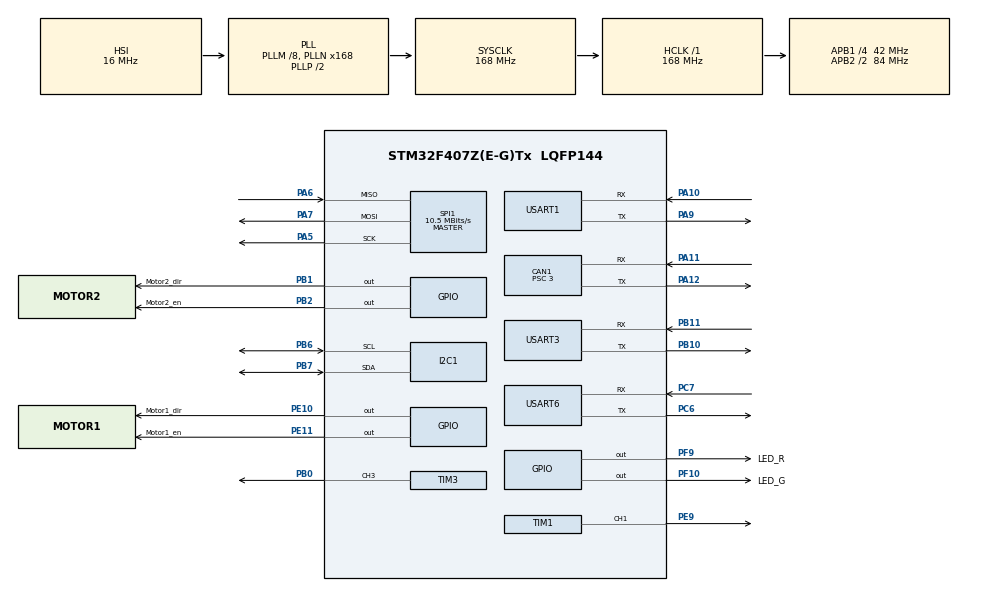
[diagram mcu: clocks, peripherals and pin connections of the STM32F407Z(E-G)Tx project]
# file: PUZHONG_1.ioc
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CAN1.ABOM=ENABLE
CAN1.BS1=CAN_BS1_10TQ
CAN1.BS2=CAN_BS2_3TQ
CAN1.CalculateBaudRate=1000000
CAN1.CalculateTimeBit=1000
CAN1.CalculateTimeQuantum=71.42857142857143
CAN1.Prescaler=3
Dma.Request0=USART3_RX
Dma.Request1=USART1_RX
Dma.Request2=USART1_TX
Dma.Request3=USART6_RX
Dma.Request4=USART3_TX
Dma.Request5=TIM1_CH1
Dma.TIM1_CH1.5.Direction=DMA_MEMORY_TO_PERIPH
Dma.TIM1_CH1.5.FIFOMode=DMA_FIFOMODE_DISABLE
Dma.TIM1_CH1.5.Instance=DMA2_Stream1
Dma.TIM1_CH1.5.MemDataAlignment=DMA_MDATAALIGN_HALFWORD
Dma.TIM1_CH1.5.MemInc=DMA_MINC_ENABLE
Dma.TIM1_CH1.5.Mode=DMA_NORMAL
Dma.TIM1_CH1.5.PeriphDataAlignment=DMA_PDATAALIGN_HALFWORD
Dma.TIM1_CH1.5.PeriphInc=DMA_PINC_DISABLE
Dma.TIM1_CH1.5.Priority=DMA_PRIORITY_MEDIUM
Dma.USART1_RX.1.Direction=DMA_PERIPH_TO_MEMORY
Dma.USART1_RX.1.FIFOMode=DMA_FIFOMODE_DISABLE
Dma.USART1_RX.1.Instance=DMA2_Stream5
Dma.USART1_RX.1.MemDataAlignment=DMA_MDATAALIGN_BYTE
Dma.USART1_RX.1.MemInc=DMA_MINC_ENABLE
Dma.USART1_RX.1.Mode=DMA_NORMAL
Dma.USART1_RX.1.PeriphDataAlignment=DMA_PDATAALIGN_BYTE
Dma.USART1_RX.1.PeriphInc=DMA_PINC_DISABLE
Dma.USART1_RX.1.Priority=DMA_PRIORITY_LOW
Dma.USART1_TX.2.Direction=DMA_MEMORY_TO_PERIPH
Dma.USART1_TX.2.FIFOMode=DMA_FIFOMODE_DISABLE
Dma.USART1_TX.2.Instance=DMA2_Stream7
Dma.USART1_TX.2.MemDataAlignment=DMA_MDATAALIGN_BYTE
Dma.USART1_TX.2.MemInc=DMA_MINC_ENABLE
Dma.USART1_TX.2.Mode=DMA_NORMAL
Dma.USART1_TX.2.PeriphDataAlignment=DMA_PDATAALIGN_BYTE
Dma.USART1_TX.2.PeriphInc=DMA_PINC_DISABLE
Dma.USART1_TX.2.Priority=DMA_PRIORITY_LOW
Dma.USART3_RX.0.Direction=DMA_PERIPH_TO_MEMORY
Dma.USART3_RX.0.FIFOMode=DMA_FIFOMODE_DISABLE
Dma.USART3_RX.0.Instance=DMA1_Stream1
Dma.USART3_RX.0.MemDataAlignment=DMA_MDATAALIGN_BYTE
Dma.USART3_RX.0.MemInc=DMA_MINC_ENABLE
Dma.USART3_RX.0.Mode=DMA_CIRCULAR
Dma.USART3_RX.0.PeriphDataAlignment=DMA_PDATAALIGN_BYTE
Dma.USART3_RX.0.PeriphInc=DMA_PINC_DISABLE
Dma.USART3_RX.0.Priority=DMA_PRIORITY_LOW
Dma.USART3_TX.4.Direction=DMA_MEMORY_TO_PERIPH
Dma.USART3_TX.4.FIFOMode=DMA_FIFOMODE_DISABLE
Dma.USART3_TX.4.Instance=DMA1_Stream3
Dma.USART3_TX.4.MemDataAlignment=DMA_MDATAALIGN_BYTE
Dma.USART3_TX.4.MemInc=DMA_MINC_ENABLE
Dma.USART3_TX.4.Mode=DMA_CIRCULAR
Dma.USART3_TX.4.PeriphDataAlignment=DMA_PDATAALIGN_BYTE
Dma.USART3_TX.4.PeriphInc=DMA_PINC_DISABLE
Dma.USART3_TX.4.Priority=DMA_PRIORITY_LOW
Dma.USART6_RX.3.Direction=DMA_PERIPH_TO_MEMORY
Dma.USART6_RX.3.FIFOMode=DMA_FIFOMODE_DISABLE
Dma.USART6_RX.3.Instance=DMA2_Stream2
Dma.USART6_RX.3.MemDataAlignment=DMA_MDATAALIGN_BYTE
Dma.USART6_RX.3.MemInc=DMA_MINC_ENABLE
Dma.USART6_RX.3.Mode=DMA_NORMAL
Dma.USART6_RX.3.PeriphDataAlignment=DMA_PDATAALIGN_BYTE
Dma.USART6_RX.3.PeriphInc=DMA_PINC_DISABLE
Dma.USART6_RX.3.Priority=DMA_PRIORITY_LOW
FREERTOS.BinarySemaphores01=can_cmd_sem,Dynamic,NULL,Available
FREERTOS.INCLUDE_eTaskGetState=1
FREERTOS.INCLUDE_pcTaskGetTaskName=1
FREERTOS.INCLUDE_uxTaskGetStackHighWaterMark=1
FREERTOS.INCLUDE_uxTaskGetStackHighWaterMark2=1
FREERTOS.INCLUDE_vTaskCleanUpResources=1
FREERTOS.INCLUDE_vTaskDelayUntil=1
FREERTOS.INCLUDE_xQueueGetMutexHolder=1
FREERTOS.INCLUDE_xSemaphoreGetMutexHolder=1
FREERTOS.INCLUDE_xTaskAbortDelay=1
FREERTOS.INCLUDE_xTaskGetCurrentTaskHandle=1
FREERTOS.INCLUDE_xTaskGetHandle=1
FREERTOS.Tasks01=StartINSTask,3,256,INS_Task,As weak,NULL,Dynamic,NULL,NULL;StartUserTask,3,256,User_Task,As weak,NULL,Dynamic,NULL,NULL;StartCanTask,-3,256,Can_Task,As weak,NULL,Dynamic,NULL,NULL;StartRosTask,-3,256,Ros_Task,As weak,NULL,Dynamic,NULL,NULL;StartGimbalTask,-3,256,Gimbal_Task,As weak,NULL,Dynamic,NULL,NULL
FREERTOS.configMINIMAL_STACK_SIZE=256
FREERTOS.configUSE_NEWLIB_REENTRANT=1
Mcu.Family=STM32F4
Mcu.Name=STM32F407Z(E-G)Tx
Mcu.Package=LQFP144
NVIC.CAN1_RX0_IRQn=true\:5\:0\:false\:false\:true\:true\:true\:true\:true
NVIC.DMA1_Stream1_IRQn=true\:5\:0\:false\:false\:true\:true\:false\:true\:true
NVIC.DMA1_Stream3_IRQn=true\:5\:0\:false\:false\:true\:true\:false\:true\:true
NVIC.DMA2_Stream1_IRQn=true\:5\:0\:false\:false\:true\:false\:false\:true\:true
NVIC.DMA2_Stream2_IRQn=true\:5\:0\:false\:false\:true\:true\:false\:true\:true
NVIC.DMA2_Stream5_IRQn=true\:5\:0\:false\:false\:true\:false\:false\:true\:true
NVIC.DMA2_Stream7_IRQn=true\:5\:0\:false\:false\:true\:true\:false\:true\:true
NVIC.PriorityGroup=NVIC_PRIORITYGROUP_4
NVIC.TIM1_UP_TIM10_IRQn=true\:5\:0\:true\:false\:true\:true\:true\:true\:true
NVIC.TIM2_IRQn=true\:5\:0\:true\:false\:true\:false\:false\:true\:true
NVIC.TIM3_IRQn=true\:5\:0\:false\:false\:true\:true\:true\:true\:true
NVIC.TimeBase=TIM2_IRQn
NVIC.TimeBaseIP=TIM2
NVIC.USART1_IRQn=true\:6\:0\:true\:false\:true\:true\:true\:true\:true
NVIC.USART3_IRQn=true\:5\:0\:false\:false\:true\:true\:true\:true\:true
NVIC.USART6_IRQn=true\:5\:0\:false\:false\:true\:true\:true\:true\:true
PA10.Mode=Asynchronous
PA10.Signal=USART1_RX
PA11.Mode=CAN_Activate
PA11.Signal=CAN1_RX
PA12.Mode=CAN_Activate
PA12.Signal=CAN1_TX
PA13.Mode=Serial_Wire
PA13.Signal=SYS_JTMS-SWDIO
PA14.Mode=Serial_Wire
PA14.Signal=SYS_JTCK-SWCLK
PA5.Mode=Full_Duplex_Master
PA5.Signal=SPI1_SCK
PA6.Mode=Full_Duplex_Master
PA6.Signal=SPI1_MISO
PA7.Mode=Full_Duplex_Master
PA7.Signal=SPI1_MOSI
PA9.Mode=Asynchronous
PA9.Signal=USART1_TX
PB0.Signal=S_TIM3_CH3
PB1.GPIO_Label=Motor2_dir
PB1.GPIO_PuPd=GPIO_PULLUP
PB1.GPIO_Speed=GPIO_SPEED_FREQ_HIGH
PB1.Signal=GPIO_Output
PB10.Mode=Asynchronous
PB10.Signal=USART3_TX
PB11.Mode=Asynchronous
PB11.Signal=USART3_RX
PB2.GPIO_Label=Motor2_en
PB2.GPIO_ModeDefaultOutputPP=GPIO_MODE_OUTPUT_PP
PB2.GPIO_PuPd=GPIO_PULLUP
PB2.GPIO_Speed=GPIO_SPEED_FREQ_MEDIUM
PB2.Signal=GPIO_Output
PB6.Mode=I2C
PB6.Signal=I2C1_SCL
PB7.Mode=I2C
PB7.Signal=I2C1_SDA
PC6.Mode=Asynchronous
PC6.Signal=USART6_TX
PC7.Mode=Asynchronous
PC7.Signal=USART6_RX
PE10.GPIO_Label=Motor1_dir
PE10.GPIO_PuPd=GPIO_PULLUP
PE10.GPIO_Speed=GPIO_SPEED_FREQ_HIGH
PE10.Signal=GPIO_Output
PE11.GPIO_Label=Motor1_en
PE11.GPIO_PuPd=GPIO_PULLUP
PE11.GPIO_Speed=GPIO_SPEED_FREQ_HIGH
PE11.Signal=GPIO_Output
PE9.Signal=S_TIM1_CH1
PF10.GPIO_Label=LED_G
PF10.GPIO_Speed=GPIO_SPEED_FREQ_MEDIUM
PF10.PinState=GPIO_PIN_SET
PF10.Signal=GPIO_Output
PF9.GPIO_Label=LED_R
PF9.GPIO_PuPd=GPIO_PULLUP
PF9.GPIO_Speed=GPIO_SPEED_FREQ_MEDIUM
PF9.PinState=GPIO_PIN_SET
PF9.Signal=GPIO_Output
PH0-OSC_IN.Mode=HSE-External-Oscillator
PH0-OSC_IN.Signal=RCC_OSC_IN
PH1-OSC_OUT.Mode=HSE-External-Oscillator
PH1-OSC_OUT.Signal=RCC_OSC_OUT
ProjectManager.HeapSize=0x200
ProjectManager.StackSize=0x400
ProjectManager.TargetToolchain=STM32CubeIDE
RCC.48MHZClocksFreq_Value=84000000
RCC.AHBFreq_Value=168000000
RCC.APB1CLKDivider=RCC_HCLK_DIV4
RCC.APB1Freq_Value=42000000
RCC.APB1TimFreq_Value=84000000
RCC.APB2CLKDivider=RCC_HCLK_DIV2
RCC.APB2Freq_Value=84000000
RCC.APB2TimFreq_Value=168000000
RCC.CortexFreq_Value=168000000
RCC.HCLKFreq_Value=168000000
RCC.HSE_VALUE=12000000
RCC.HSI_VALUE=16000000
RCC.LSE_VALUE=32768
RCC.PLLM=8
RCC.PLLN=168
RCC.SYSCLKFreq_VALUE=168000000
RCC.SYSCLKSource=RCC_SYSCLKSOURCE_PLLCLK
RCC.VCOOutputFreq_Value=336000000
SH.S_TIM1_CH1.0=TIM1_CH1,PWM Generation1 CH1
SH.S_TIM3_CH3.0=TIM3_CH3,PWM Generation3 CH3
SPI1.BaudRatePrescaler=SPI_BAUDRATEPRESCALER_8
SPI1.CLKPhase=SPI_PHASE_2EDGE
SPI1.CLKPolarity=SPI_POLARITY_LOW
SPI1.CalculateBaudRate=10.5 MBits/s
SPI1.Direction=SPI_DIRECTION_2LINES
SPI1.Mode=SPI_MODE_MASTER
SPI1.VirtualType=VM_MASTER
TIM1.Channel-PWM\ Generation1\ CH1=TIM_CHANNEL_1
TIM1.Period=1000-1
TIM1.Prescaler=84-1
TIM3.Channel-PWM\ Generation3\ CH3=TIM_CHANNEL_3
TIM3.Period=1000
TIM3.Prescaler=42-1
USART1.VirtualMode=VM_ASYNC
USART3.VirtualMode=VM_ASYNC
USART6.VirtualMode=VM_ASYNC
VP_FREERTOS_VS_CMSIS_V1.Mode=CMSIS_V1
VP_SYS_VS_tim2.Mode=TIM2
VP_TIM1_VS_ClockSourceINT.Mode=Internal
VP_TIM3_VS_ClockSourceINT.Mode=Internal
board=custom

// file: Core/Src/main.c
/* USER CODE BEGIN Header */
/**
  ******************************************************************************
  * @file           : main.c
  * @brief          : Main program body
  ******************************************************************************
  * @attention
  *
  * Copyright (c) 2025 STMicroelectronics.
  * All rights reserved.
  *
  * This software is licensed under terms that can be found in the LICENSE file
  * in the root directory of this software component.
  * If no LICENSE file comes with this software, it is provided AS-IS.
  *
  ******************************************************************************
  */
/* USER CODE END Header */
#include "main.h"
#include "cmsis_os.h"
#include "can.h"
#include "dma.h"
#include "i2c.h"
#include "spi.h"
#include "tim.h"
#include "usart.h"
#include "gpio.h"

/* USER CODE BEGIN Includes */
// #include "stepper_pwm_control.h"
/* USER CODE END Includes */

void SystemClock_Config(void);
void MX_FREERTOS_Init(void);

int main(void)
{

  /* MCU Configuration--------------------------------------------------------*/

  /* Reset of all peripherals, Initializes the Flash interface and the Systick. */
  HAL_Init();

  /* Configure the system clock */
  SystemClock_Config();

  /* Initialize all configured peripherals */
  MX_GPIO_Init();
  MX_DMA_Init();
  MX_CAN1_Init();
  MX_I2C1_Init();
  MX_SPI1_Init();
  MX_TIM1_Init();
  MX_USART1_UART_Init();
  MX_USART3_UART_Init();
  MX_TIM3_Init();
  MX_USART6_UART_Init();
  /* USER CODE BEGIN 2 */
  MCU_Init();
  /* USER CODE END 2 */

  /* Call init function for freertos objects (in cmsis_os2.c) */
  MX_FREERTOS_Init();

  /* Start scheduler */
  osKernelStart();

  /* We should never get here as control is now taken by the scheduler */

  /* Infinite loop */
  while (1)
  {

  }
}

void SystemClock_Config(void)
{
  RCC_OscInitTypeDef RCC_OscInitStruct = {0};
  RCC_ClkInitTypeDef RCC_ClkInitStruct = {0};

  /** Configure the main internal regulator output voltage
  */
  __HAL_RCC_PWR_CLK_ENABLE();
  __HAL_PWR_VOLTAGESCALING_CONFIG(PWR_REGULATOR_VOLTAGE_SCALE1);

  /** Initializes the RCC Oscillators according to the specified parameters
  * in the RCC_OscInitTypeDef structure.
  */
  RCC_OscInitStruct.OscillatorType = RCC_OSCILLATORTYPE_HSI;
  RCC_OscInitStruct.HSIState = RCC_HSI_ON;
  RCC_OscInitStruct.HSICalibrationValue = RCC_HSICALIBRATION_DEFAULT;
  RCC_OscInitStruct.PLL.PLLState = RCC_PLL_ON;
  RCC_OscInitStruct.PLL.PLLSource = RCC_PLLSOURCE_HSI;
  RCC_OscInitStruct.PLL.PLLM = 8;
  RCC_OscInitStruct.PLL.PLLN = 168;
  RCC_OscInitStruct.PLL.PLLP = RCC_PLLP_DIV2;
  RCC_OscInitStruct.PLL.PLLQ = 4;
  if (HAL_RCC_OscConfig(&RCC_OscInitStruct) != HAL_OK)
  {
    Error_Handler();
  }

  /** Initializes the CPU, AHB and APB buses clocks
  */
  RCC_ClkInitStruct.ClockType = RCC_CLOCKTYPE_HCLK|RCC_CLOCKTYPE_SYSCLK
                              |RCC_CLOCKTYPE_PCLK1|RCC_CLOCKTYPE_PCLK2;
  RCC_ClkInitStruct.SYSCLKSource = RCC_SYSCLKSOURCE_PLLCLK;
  RCC_ClkInitStruct.AHBCLKDivider = RCC_SYSCLK_DIV1;
  RCC_ClkInitStruct.APB1CLKDivider = RCC_HCLK_DIV4;
  RCC_ClkInitStruct.APB2CLKDivider = RCC_HCLK_DIV2;

  if (HAL_RCC_ClockConfig(&RCC_ClkInitStruct, FLASH_LATENCY_5) != HAL_OK)
  {
    Error_Handler();
  }
}

/* USER CODE BEGIN 4 */
// void HAL_TIM_OC_DelayElapsedCallback(TIM_HandleTypeDef *htim)
// {
//   if (htim->Instance == TIM1 && htim->Channel == HAL_TIM_ACTIVE_CHANNEL_1)
//   {
//     Stepper_PulseCallback(htim);  // 这里表示上升沿来了，真正走了一个脉冲
//   }
//   else if (htim->Instance == TIM3 && htim->Channel == HAL_TIM_ACTIVE_CHANNEL_1)
//   {
//     Stepper_PulseCallback(htim);
//   }
// }
// void HAL_TIM_OC_DelayElapsedCallback(TIM_HandleTypeDef *htim)
// {
//   Stepper_PulseCallback(htim);
// }

/* USER CODE END 4 */

void HAL_TIM_PeriodElapsedCallback(TIM_HandleTypeDef *htim)
{
  if (htim->Instance == TIM2)
  {
    HAL_IncTick();
  }
  /* USER CODE BEGIN Callback 1 */
  // else if (htim->Instance == TIM1||htim->Instance == TIM3)
  // {
  //   Stepper_PulseCallback(htim);  // 关键：用于计数脉冲
  // }
  // else if (htim->Instance == TIM3)
  // {
  //   Stepper_PulseCallback(htim);  // 关键：用于计数脉冲
  // }
  /* USER CODE END Callback 1 */
}

void Error_Handler(void)
{
  __disable_irq();
  while (1)
  {
  }
}

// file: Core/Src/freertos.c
/* USER CODE BEGIN Header */
/**
  ******************************************************************************
  * File Name          : freertos.c
  * Description        : Code for freertos applications
  ******************************************************************************
  * @attention
  *
  * Copyright (c) 2025 STMicroelectronics.
  * All rights reserved.
  *
  * This software is licensed under terms that can be found in the LICENSE file
  * in the root directory of this software component.
  * If no LICENSE file comes with this software, it is provided AS-IS.
  *
  ******************************************************************************
  */
/* USER CODE END Header */

#include "FreeRTOS.h"
// #include "freertos_config.h"
#include "task.h"
#include "main.h"
#include "cmsis_os.h"

osThreadId StartINSTaskHandle;
osThreadId StartUserTaskHandle;
osThreadId StartCanTaskHandle;
osThreadId StartRosTaskHandle;
osThreadId StartGimbalTaskHandle;
osSemaphoreId can_cmd_semHandle;

void INS_Task(void const * argument);
void User_Task(void const * argument);
void Can_Task(void const * argument);
void Ros_Task(void const * argument);
void Gimbal_Task(void const * argument);

void MX_FREERTOS_Init(void); /* (MISRA C 2004 rule 8.1) */

/* GetIdleTaskMemory prototype (linked to static allocation support) */
void vApplicationGetIdleTaskMemory( StaticTask_t **ppxIdleTaskTCBBuffer, StackType_t **ppxIdleTaskStackBuffer, uint32_t *pulIdleTaskStackSize );

/* USER CODE BEGIN GET_IDLE_TASK_MEMORY */
static StaticTask_t xIdleTaskTCBBuffer;
static StackType_t xIdleStack[configMINIMAL_STACK_SIZE];

void vApplicationGetIdleTaskMemory( StaticTask_t **ppxIdleTaskTCBBuffer, StackType_t **ppxIdleTaskStackBuffer, uint32_t *pulIdleTaskStackSize )
{
  *ppxIdleTaskTCBBuffer = &xIdleTaskTCBBuffer;
  *ppxIdleTaskStackBuffer = &xIdleStack[0];
  *pulIdleTaskStackSize = configMINIMAL_STACK_SIZE;
  /* place for user code */
}
/* USER CODE END GET_IDLE_TASK_MEMORY */

void MX_FREERTOS_Init(void) {

  /* Create the semaphores(s) */
  /* definition and creation of can_cmd_sem */
  osSemaphoreDef(can_cmd_sem);
  can_cmd_semHandle = osSemaphoreCreate(osSemaphore(can_cmd_sem), 1);

  /* Create the thread(s) */
  /* definition and creation of StartINSTask */
  osThreadDef(StartINSTask, INS_Task, osPriorityRealtime, 0, 256);
  StartINSTaskHandle = osThreadCreate(osThread(StartINSTask), NULL);

  /* definition and creation of StartUserTask */
  osThreadDef(StartUserTask, User_Task, osPriorityRealtime, 0, 256);
  StartUserTaskHandle = osThreadCreate(osThread(StartUserTask), NULL);

  /* definition and creation of StartCanTask */
  osThreadDef(StartCanTask, Can_Task, osPriorityIdle, 0, 256);
  StartCanTaskHandle = osThreadCreate(osThread(StartCanTask), NULL);

  /* definition and creation of StartRosTask */
  osThreadDef(StartRosTask, Ros_Task, osPriorityIdle, 0, 256);
  StartRosTaskHandle = osThreadCreate(osThread(StartRosTask), NULL);

  /* definition and creation of StartGimbalTask */
  osThreadDef(StartGimbalTask, Gimbal_Task, osPriorityIdle, 0, 256);
  StartGimbalTaskHandle = osThreadCreate(osThread(StartGimbalTask), NULL);

}

__weak void INS_Task(void const * argument)
{
  for(;;)
  {
    osDelay(1);
  }
}

__weak void User_Task(void const * argument)
{
  for(;;)
  {
    osDelay(1);
  }
}

__weak void Can_Task(void const * argument)
{
  for(;;)
  {
    osDelay(1);
  }
}

__weak void Ros_Task(void const * argument)
{
  for(;;)
  {
    osDelay(1);
  }
}

__weak void Gimbal_Task(void const * argument)
{
  for(;;)
  {
    osDelay(1);
  }
}
